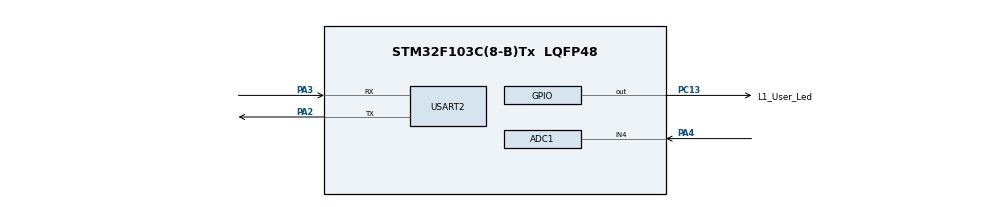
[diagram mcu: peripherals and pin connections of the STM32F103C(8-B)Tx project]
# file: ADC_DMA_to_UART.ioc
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Mcu.Family=STM32F1
Dma.ADC1.0.Instance=DMA1_Channel1
ADC1.Rank-0\#ChannelRegularConversion=1
ADC1.ContinuousConvMode=ENABLE
PC13-TAMPER-RTC.Signal=GPIO_Output
VP_SYS_VS_ND.Mode=No_Debug
ProjectManager.StackSize=0x400
PA3.Mode=Asynchronous
Dma.ADC1.0.PeriphDataAlignment=DMA_PDATAALIGN_HALFWORD
ProjectManager.TargetToolchain=STM32CubeIDE
Dma.ADC1.0.Mode=DMA_CIRCULAR
Dma.ADC1.0.Priority=DMA_PRIORITY_LOW
Dma.ADC1.0.Direction=DMA_PERIPH_TO_MEMORY
Dma.ADC1.0.MemDataAlignment=DMA_MDATAALIGN_HALFWORD
ADC1.Channel-0\#ChannelRegularConversion=ADC_CHANNEL_4
board=custom
PC13-TAMPER-RTC.GPIO_Label=L1_User_Led
RCC.APB2Freq_Value=8000000
Dma.ADC1.0.PeriphInc=DMA_PINC_DISABLE
SH.ADCx_IN4.0=ADC1_IN4,IN4
Mcu.Name=STM32F103C(8-B)Tx
ADC1.SamplingTime-0\#ChannelRegularConversion=ADC_SAMPLETIME_1CYCLE_5
PA2.Signal=USART2_TX
PA4.Signal=ADCx_IN4
Mcu.Package=LQFP48
ADC1.master=1
USART2.VirtualMode=VM_ASYNC
PC13-TAMPER-RTC.GPIO_PuPd=GPIO_PULLDOWN
Dma.ADC1.0.MemInc=DMA_MINC_ENABLE
ProjectManager.HeapSize=0x200
NVIC.PriorityGroup=NVIC_PRIORITYGROUP_4
ADC1.NbrOfConversionFlag=1
PA2.Mode=Asynchronous
NVIC.DMA1_Channel1_IRQn=true\:0\:0\:false\:false\:true\:false\:true
Dma.Request0=ADC1
RCC.APB1Freq_Value=8000000
PA3.Signal=USART2_RX

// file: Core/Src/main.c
/* USER CODE BEGIN Header */
/**
  ******************************************************************************
  * @file           : main.c
  * @brief          : Main program body
  ******************************************************************************
  * @attention
  *
  * <h2><center>&copy; Copyright (c) 2021 STMicroelectronics.
  * All rights reserved.</center></h2>
  *
  * This software component is licensed by ST under BSD 3-Clause license,
  * the "License"; You may not use this file except in compliance with the
  * License. You may obtain a copy of the License at:
  *                        opensource.org/licenses/BSD-3-Clause
  *
  ******************************************************************************
  */
/* USER CODE END Header */
#include "main.h"

ADC_HandleTypeDef hadc1;
DMA_HandleTypeDef hdma_adc1;

UART_HandleTypeDef huart2;

/* USER CODE BEGIN PV */
uint16_t adc_buf[4096];

/* USER CODE END PV */

void SystemClock_Config(void);
static void MX_GPIO_Init(void);
static void MX_DMA_Init(void);
static void MX_USART2_UART_Init(void);
static void MX_ADC1_Init(void);

int main(void)
{

  /* MCU Configuration--------------------------------------------------------*/

  /* Reset of all peripherals, Initializes the Flash interface and the Systick. */
  HAL_Init();

  /* Configure the system clock */
  SystemClock_Config();

  /* Initialize all configured peripherals */
  MX_GPIO_Init();
  MX_DMA_Init();
  MX_USART2_UART_Init();
  MX_ADC1_Init();
  /* USER CODE BEGIN 2 */
  //Starting ADC Conversion
  HAL_ADC_Start_DMA(&hadc1, (uint32_t*)adc_buf, 4096);
  /* USER CODE END 2 */

  /* Infinite loop */
  while (1)
  {

  }
}

void SystemClock_Config(void)
{
  RCC_OscInitTypeDef RCC_OscInitStruct = {0};
  RCC_ClkInitTypeDef RCC_ClkInitStruct = {0};
  RCC_PeriphCLKInitTypeDef PeriphClkInit = {0};

  /** Initializes the RCC Oscillators according to the specified parameters
  * in the RCC_OscInitTypeDef structure.
  */
  RCC_OscInitStruct.OscillatorType = RCC_OSCILLATORTYPE_HSI;
  RCC_OscInitStruct.HSIState = RCC_HSI_ON;
  RCC_OscInitStruct.HSICalibrationValue = RCC_HSICALIBRATION_DEFAULT;
  RCC_OscInitStruct.PLL.PLLState = RCC_PLL_NONE;
  if (HAL_RCC_OscConfig(&RCC_OscInitStruct) != HAL_OK)
  {
    Error_Handler();
  }
  /** Initializes the CPU, AHB and APB buses clocks
  */
  RCC_ClkInitStruct.ClockType = RCC_CLOCKTYPE_HCLK|RCC_CLOCKTYPE_SYSCLK
                              |RCC_CLOCKTYPE_PCLK1|RCC_CLOCKTYPE_PCLK2;
  RCC_ClkInitStruct.SYSCLKSource = RCC_SYSCLKSOURCE_HSI;
  RCC_ClkInitStruct.AHBCLKDivider = RCC_SYSCLK_DIV1;
  RCC_ClkInitStruct.APB1CLKDivider = RCC_HCLK_DIV1;
  RCC_ClkInitStruct.APB2CLKDivider = RCC_HCLK_DIV1;

  if (HAL_RCC_ClockConfig(&RCC_ClkInitStruct, FLASH_LATENCY_0) != HAL_OK)
  {
    Error_Handler();
  }
  PeriphClkInit.PeriphClockSelection = RCC_PERIPHCLK_ADC;
  PeriphClkInit.AdcClockSelection = RCC_ADCPCLK2_DIV2;
  if (HAL_RCCEx_PeriphCLKConfig(&PeriphClkInit) != HAL_OK)
  {
    Error_Handler();
  }
}

static void MX_ADC1_Init(void)
{

  ADC_ChannelConfTypeDef sConfig = {0};

  /** Common config
  */
  hadc1.Instance = ADC1;
  hadc1.Init.ScanConvMode = ADC_SCAN_DISABLE;
  hadc1.Init.ContinuousConvMode = ENABLE;
  hadc1.Init.DiscontinuousConvMode = DISABLE;
  hadc1.Init.ExternalTrigConv = ADC_SOFTWARE_START;
  hadc1.Init.DataAlign = ADC_DATAALIGN_RIGHT;
  hadc1.Init.NbrOfConversion = 1;
  if (HAL_ADC_Init(&hadc1) != HAL_OK)
  {
    Error_Handler();
  }
  /** Configure Regular Channel
  */
  sConfig.Channel = ADC_CHANNEL_4;
  sConfig.Rank = ADC_REGULAR_RANK_1;
  sConfig.SamplingTime = ADC_SAMPLETIME_1CYCLE_5;
  if (HAL_ADC_ConfigChannel(&hadc1, &sConfig) != HAL_OK)
  {
    Error_Handler();
  }

}

static void MX_USART2_UART_Init(void)
{

  huart2.Instance = USART2;
  huart2.Init.BaudRate = 115200;
  huart2.Init.WordLength = UART_WORDLENGTH_8B;
  huart2.Init.StopBits = UART_STOPBITS_1;
  huart2.Init.Parity = UART_PARITY_NONE;
  huart2.Init.Mode = UART_MODE_TX_RX;
  huart2.Init.HwFlowCtl = UART_HWCONTROL_NONE;
  huart2.Init.OverSampling = UART_OVERSAMPLING_16;
  if (HAL_UART_Init(&huart2) != HAL_OK)
  {
    Error_Handler();
  }

}

static void MX_DMA_Init(void)
{

  /* DMA controller clock enable */
  __HAL_RCC_DMA1_CLK_ENABLE();

  /* DMA interrupt init */
  /* DMA1_Channel1_IRQn interrupt configuration */
  HAL_NVIC_SetPriority(DMA1_Channel1_IRQn, 0, 0);
  HAL_NVIC_EnableIRQ(DMA1_Channel1_IRQn);

}

static void MX_GPIO_Init(void)
{
  GPIO_InitTypeDef GPIO_InitStruct = {0};

  /* GPIO Ports Clock Enable */
  __HAL_RCC_GPIOC_CLK_ENABLE();
  __HAL_RCC_GPIOA_CLK_ENABLE();

  /*Configure GPIO pin Output Level */
  HAL_GPIO_WritePin(L1_User_Led_GPIO_Port, L1_User_Led_Pin, GPIO_PIN_RESET);

  /*Configure GPIO pin : L1_User_Led_Pin */
  GPIO_InitStruct.Pin = L1_User_Led_Pin;
  GPIO_InitStruct.Mode = GPIO_MODE_OUTPUT_PP;
  GPIO_InitStruct.Pull = GPIO_PULLDOWN;
  GPIO_InitStruct.Speed = GPIO_SPEED_FREQ_LOW;
  HAL_GPIO_Init(L1_User_Led_GPIO_Port, &GPIO_InitStruct);

}

/* USER CODE BEGIN 4 */
//called when half of the buffer is filled
void HAL_ADC_ConvHalfCpltCallback(ADC_HandleTypeDef* hadc)
{
	HAL_GPIO_WritePin(L1_User_Led_GPIO_Port, L1_User_Led_Pin, 1);
}

//called when complete of the buffer is filled
void HAL_ADC_ConvCpltCallback(ADC_HandleTypeDef* hadc)
{
	HAL_GPIO_WritePin(L1_User_Led_GPIO_Port, L1_User_Led_Pin, 0);
}
/* USER CODE END 4 */

void Error_Handler(void)
{
  __disable_irq();
  while (1)
  {
  }
}

/************************ (C) COPYRIGHT STMicroelectronics *****END OF FILE****/
